# HDSC_HC32F460KETA register map
Vendor: HDSC Co.,Ltd.; Series: ARMCM4; File version: 1.0
CPU: CM4 r0p1, little endian, MPU, FPU, 4 interrupt priority bits
Registers are 32-bit, read-write, reset 0x0 unless marked. A register's access mark holds for its fields unless they carry their own. Offsets are from the block's base; [hi:lo] are bit positions; {n}, {i} and the like mark numbered series.

## SYSREG
Base 0x40054000
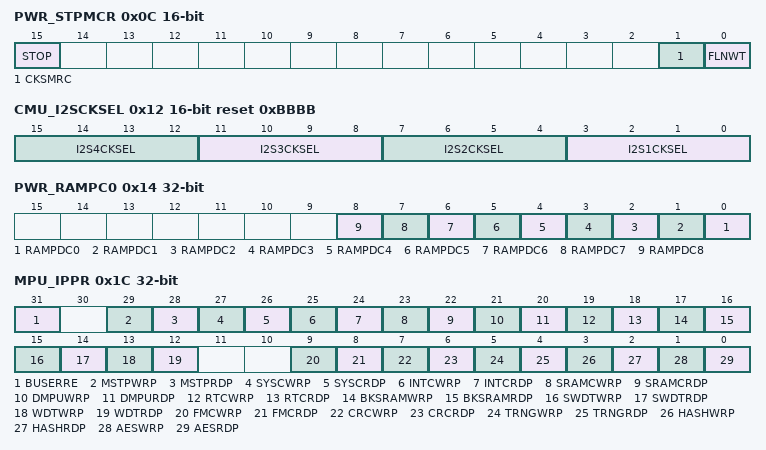
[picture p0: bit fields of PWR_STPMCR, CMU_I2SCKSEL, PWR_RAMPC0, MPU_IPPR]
0x0C PWR_STPMCR 16-bit
  [15] STOP, [1] CKSMRC, [0] FLNWT
0x10 CMU_PERICKSEL 16-bit
  [3:0] PERICKSEL
0x12 CMU_I2SCKSEL 16-bit reset 0xBBBB
  [4n-1:4n-4] I2S{n}CKSEL (n=1..4)
0x14 PWR_RAMPC0
  [n] RAMPDC{n} (n=0..8)
0x18 PWR_RAMOPM reset 0x8043
  [15:0] RAMOPM
0x1C MPU_IPPR
  [31] BUSERRE, [29] MSTPWRP, [28] MSTPRDP, [27] SYSCWRP, [26] SYSCRDP, [25] INTCWRP, [24] INTCRDP, [23] SRAMCWRP, [22] SRAMCRDP, [21] DMPUWRP, [20] DMPURDP, [19] RTCWRP, [18] RTCRDP, [17] BKSRAMWRP, [16] BKSRAMRDP, [15] SWDTWRP, [14] SWDTRDP, [13] WDTWRP, [12] WDTRDP, [9] FMCWRP, [8] FMCRDP, [7] CRCWRP, [6] CRCRDP, [5] TRNGWRP, [4] TRNGRDP, [3] HASHWRP, [2] HASHRDP, [1] AESWRP, [0] AESRDP
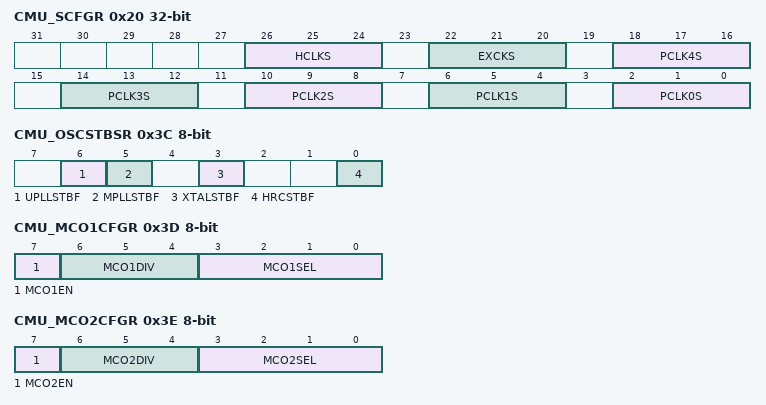
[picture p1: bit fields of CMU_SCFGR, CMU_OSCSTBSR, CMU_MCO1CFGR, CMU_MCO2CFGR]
0x20 CMU_SCFGR
  [26:24] HCLKS, [22:20] EXCKS, [4n+2:4n] PCLK{n}S (n=0..4)
0x24 CMU_UFSCKCFGR 8-bit reset 0x40
  [7:4] USBCKS
0x26 CMU_CKSWR 8-bit reset 0x1
  [2:0] CKSW
0x2A CMU_PLLCR 8-bit reset 0x1
  [0] MPLLOFF
0x2E CMU_UPLLCR 8-bit reset 0x1
  [0] UPLLOFF
0x32 CMU_XTALCR 8-bit reset 0x1
  [0] XTALSTP
0x36 CMU_HRCCR 8-bit reset 0x1
  [0] HRCSTP
0x38 CMU_MRCCR 8-bit reset 0x80
  [0] MRCSTP
0x3C CMU_OSCSTBSR 8-bit
  [6] UPLLSTBF, [5] MPLLSTBF, [3] XTALSTBF, [0] HRCSTBF
0x3D CMU_MCO1CFGR 8-bit
  [7] MCO1EN, [6:4] MCO1DIV, [3:0] MCO1SEL
0x3E CMU_MCO2CFGR 8-bit
  [7] MCO2EN, [6:4] MCO2DIV, [3:0] MCO2SEL
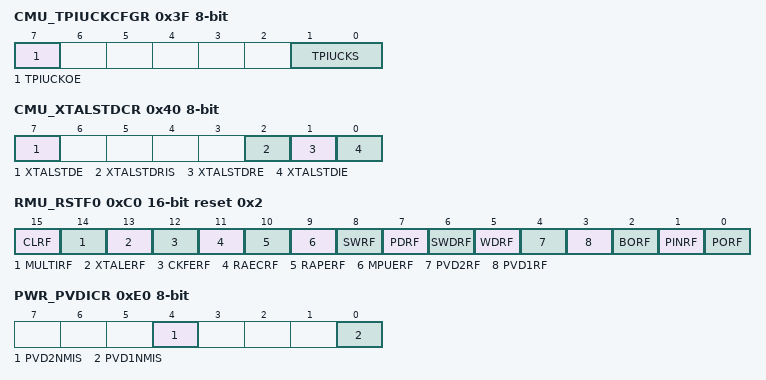
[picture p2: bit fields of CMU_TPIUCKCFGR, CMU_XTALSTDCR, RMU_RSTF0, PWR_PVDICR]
0x3F CMU_TPIUCKCFGR 8-bit
  [7] TPIUCKOE, [1:0] TPIUCKS
0x40 CMU_XTALSTDCR 8-bit
  [7] XTALSTDE, [2] XTALSTDRIS, [1] XTALSTDRE, [0] XTALSTDIE
0x41 CMU_XTALSTDSR 8-bit
  [0] XTALSTDF
0x61 CMU_MRCTRM 8-bit
0x62 CMU_HRCTRM 8-bit
0xA2 CMU_XTALSTBCR 8-bit reset 0x5
  [3:0] XTALSTB
0xC0 RMU_RSTF0 16-bit reset 0x2
  [15] CLRF, [14] MULTIRF, [13] XTALERF, [12] CKFERF, [11] RAECRF, [10] RAPERF, [9] MPUERF, [8] SWRF, [7] PDRF, [6] SWDRF, [5] WDRF, [4] PVD2RF, [3] PVD1RF, [2] BORF, [1] PINRF, [0] PORF
0xE0 PWR_PVDICR 8-bit
  [4] PVD2NMIS, [0] PVD1NMIS
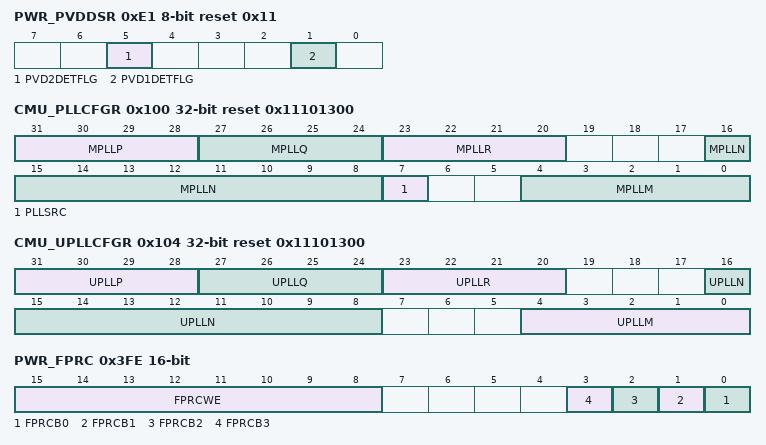
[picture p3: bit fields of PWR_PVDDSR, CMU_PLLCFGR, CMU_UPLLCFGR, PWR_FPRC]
0xE1 PWR_PVDDSR 8-bit reset 0x11
  [5] PVD2DETFLG, [1] PVD1DETFLG
0x100 CMU_PLLCFGR reset 0x11101300
  [31:28] MPLLP, [27:24] MPLLQ, [23:20] MPLLR, [16:8] MPLLN, [7] PLLSRC, [4:0] MPLLM
0x104 CMU_UPLLCFGR reset 0x11101300
  [31:28] UPLLP, [27:24] UPLLQ, [23:20] UPLLR, [16:8] UPLLN, [4:0] UPLLM
0x3FE PWR_FPRC 16-bit
  [15:8] FPRCWE, [n] FPRCB{n} (n=0..3)
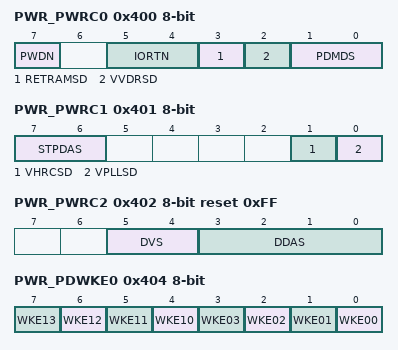
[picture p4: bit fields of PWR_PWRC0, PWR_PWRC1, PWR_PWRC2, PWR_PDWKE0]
0x400 PWR_PWRC0 8-bit
  [7] PWDN, [5:4] IORTN, [3] RETRAMSD, [2] VVDRSD, [1:0] PDMDS
0x401 PWR_PWRC1 8-bit
  [7:6] STPDAS, [1] VHRCSD, [0] VPLLSD
0x402 PWR_PWRC2 8-bit reset 0xFF
  [5:4] DVS, [3:0] DDAS
0x403 PWR_PWRC3 8-bit
  [2] PDTS
0x404 PWR_PDWKE0 8-bit
  [n-6] WKE{n} (n=10..13), [n] WKE{n:02} (n=0..3)
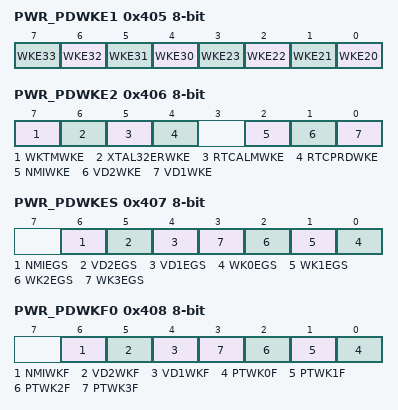
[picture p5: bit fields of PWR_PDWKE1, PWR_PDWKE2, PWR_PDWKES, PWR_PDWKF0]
0x405 PWR_PDWKE1 8-bit
  [n-26] WKE{n} (n=30..33), [n-20] WKE{n} (n=20..23)
0x406 PWR_PDWKE2 8-bit
  [7] WKTMWKE, [6] XTAL32ERWKE, [5] RTCALMWKE, [4] RTCPRDWKE, [2] NMIWKE, [1] VD2WKE, [0] VD1WKE
0x407 PWR_PDWKES 8-bit
  [6] NMIEGS, [5] VD2EGS, [4] VD1EGS, [n] WK{n}EGS (n=0..3)
0x408 PWR_PDWKF0 8-bit
  [6] NMIWKF, [5] VD2WKF, [4] VD1WKF, [n] PTWK{n}F (n=0..3)
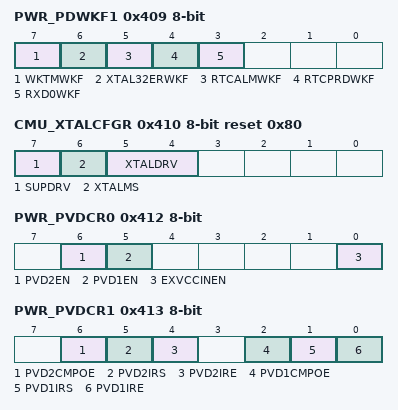
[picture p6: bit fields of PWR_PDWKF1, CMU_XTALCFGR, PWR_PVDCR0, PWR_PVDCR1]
0x409 PWR_PDWKF1 8-bit
  [7] WKTMWKF, [6] XTAL32ERWKF, [5] RTCALMWKF, [4] RTCPRDWKF, [3] RXD0WKF
0x40A PWR_PWCMR 8-bit
  [7] ADBUFE
0x40F PWR_MDSWCR 8-bit
0x410 CMU_XTALCFGR 8-bit reset 0x80
  [7] SUPDRV, [6] XTALMS, [5:4] XTALDRV
0x412 PWR_PVDCR0 8-bit
  [6] PVD2EN, [5] PVD1EN, [0] EXVCCINEN
0x413 PWR_PVDCR1 8-bit
  [6] PVD2CMPOE, [5] PVD2IRS, [4] PVD2IRE, [2] PVD1CMPOE, [1] PVD1IRS, [0] PVD1IRE
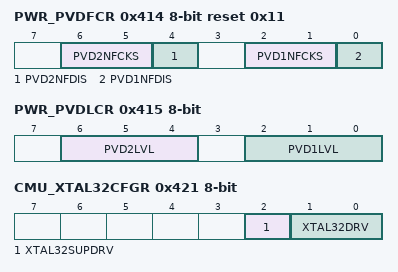
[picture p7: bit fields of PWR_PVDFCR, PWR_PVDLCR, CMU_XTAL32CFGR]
0x414 PWR_PVDFCR 8-bit reset 0x11
  [6:5] PVD2NFCKS, [4] PVD2NFDIS, [2:1] PVD1NFCKS, [0] PVD1NFDIS
0x415 PWR_PVDLCR 8-bit
  [6:4] PVD2LVL, [2:0] PVD1LVL
0x420 CMU_XTAL32CR 8-bit
  [0] XTAL32STP
0x421 CMU_XTAL32CFGR 8-bit
  [2] XTAL32SUPDRV, [1:0] XTAL32DRV
0x425 CMU_XTAL32NFR 8-bit
  [1:0] XTAL32NF
0x427 CMU_LRCCR 8-bit
  [0] LRCSTP
0x429 CMU_LRCTRM 8-bit
0x42B PWR_XTAL32CS 8-bit
  [7] CSDIS
